# BL808 register map
File version: 0.1
Registers are access not given, no defined reset value unless marked. A register's access mark holds for its fields unless they carry their own. Offsets are from the block's base; [hi:lo] are bit positions.

## IR
Base 0x2000A600
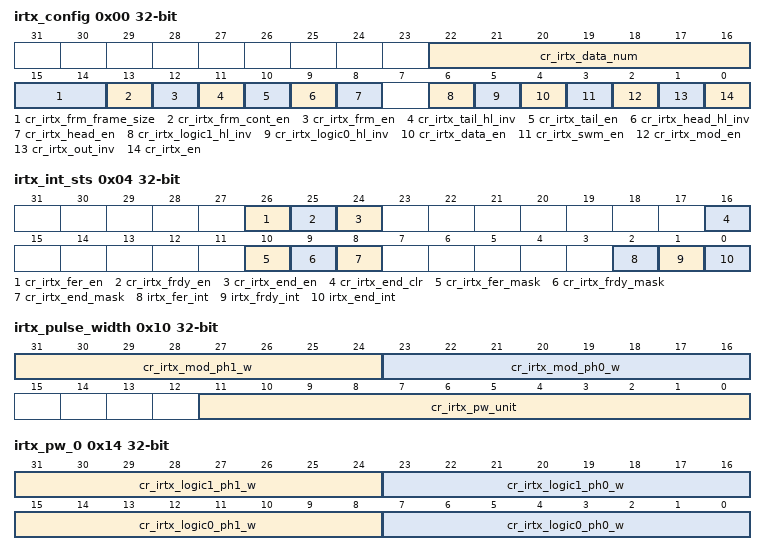
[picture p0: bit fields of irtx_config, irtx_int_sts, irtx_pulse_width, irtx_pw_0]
0x00 irtx_config
  [22:16] cr_irtx_data_num rw — Bit count of Data phase (unit: bit / PW for normal / SWM) (Don't-care if cr_irtx_frm_en is enabled)
  [15:14] cr_irtx_frm_frame_size rw — IRTX freerun mode frame size (also the valid width for each FIFO entry) 2'd0: 8-bit 2'd1: 16-bit 2'd2: 24-bit 2'd3: 32-bit
  [13] cr_irtx_frm_cont_en rw — Enable signal of IRTX freerun continuous mode 0: Disabled, each data frame is separated by an idle time (tail_ph0_w+1 + tail_ph1_w+1)*pw_unit 1: Enabled, data continuously sent without interval (if FIFO data is valid)
  [12] cr_irtx_frm_en rw — Enable signal of IRTX freerun mode (Don't care if SWM is enabled) Note: HEAD/TAIL is disabled in freerun mode
  [11] cr_irtx_tail_hl_inv rw — Tail pulse H/L inverse signal (Don't care if SWM or FRM is enabled) 0: Phase 0 is High (Active), phase 1 is Low (Idle) (H -> L) 1: Phase 0 is Low (Idle), phase 1 is High (Active) (L -> H)
  [10] cr_irtx_tail_en rw — Enable signal of tail pulse (Don't care if SWM or FRM is enabled)
  [9] cr_irtx_head_hl_inv rw — Tail pulse H/L inverse signal (Don't care if SWM or FRM is enabled) 0: Phase 0 is High (Active), phase 1 is Low (Idle) (H -> L) 1: Phase 0 is Low (Idle), phase 1 is High (Active) (L -> H)
  [8] cr_irtx_head_en rw — Enable signal of head pulse (Don't care if SWM or FRM is enabled)
  [6] cr_irtx_logic1_hl_inv rw — Logic 1 H/L inverse signal (Don't care if SWM is enabled) 0: Phase 0 is High (Active), phase 1 is Low (Idle) (H -> L) 1: Phase 0 is Low (Idle), phase 1 is High (Active) (L -> H)
  [5] cr_irtx_logic0_hl_inv rw — Logic 0 H/L inverse signal (Don't care if SWM is enabled) 0: Phase 0 is High (Active), phase 1 is Low (Idle) (H -> L) 1: Phase 0 is Low (Idle), phase 1 is High (Active) (L -> H)
  [4] cr_irtx_data_en rw — Enable signal of data phase (Don't care if SWM or FRM is enabled)
  [3] cr_irtx_swm_en rw — Enable signal of IRTX Software Mode (SWM)
  [2] cr_irtx_mod_en rw — Enable signal of output modulation
  [1] cr_irtx_out_inv rw — Output inverse signal 1'b0: Output stays at Low during idle state 1'b1: Output stays at High during idle state
  [0] cr_irtx_en rw — Enable signal of IRTX function Asserting this bit will trigger the transaction, and should be de-asserted after finish
0x04 irtx_int_sts
  [26] cr_irtx_fer_en rw — Interrupt enable of irtx_fer_int
  [25] cr_irtx_frdy_en rw — Interrupt enable of irtx_frdy_int
  [24] cr_irtx_end_en rw — Interrupt enable of irtx_end_int
  [16] cr_irtx_end_clr write-once — Interrupt clear of irtx_end_int
  [10] cr_irtx_fer_mask rw — Interrupt mask of irtx_fer_int
  [9] cr_irtx_frdy_mask rw — Interrupt mask of irtx_frdy_int
  [8] cr_irtx_end_mask rw — Interrupt mask of irtx_end_int
  [2] irtx_fer_int ro — IRTX FIFO error interrupt, auto-cleared when FIFO overflow/underflow error flag is cleared
  [1] irtx_frdy_int ro — IRTX FIFO ready (tx_fifo_cnt > tx_fifo_th) interrupt, auto-cleared when data is pushed
  [0] irtx_end_int ro — IRTX transfer end interrupt
0x10 irtx_pulse_width
  [31:24] cr_irtx_mod_ph1_w rw — Modulation phase 1 width
  [23:16] cr_irtx_mod_ph0_w rw — Modulation phase 0 width
  [11:0] cr_irtx_pw_unit rw — Pulse width unit
0x14 irtx_pw_0 rw
  [31:24] cr_irtx_logic1_ph1_w — Pulse width of logic1 phase 1 (Don't care if SWM is enabled)
  [23:16] cr_irtx_logic1_ph0_w — Pulse width of logic1 phase 0 (Don't care if SWM is enabled)
  [15:8] cr_irtx_logic0_ph1_w — Pulse width of logic0 phase 1 (Don't care if SWM is enabled)
  [7:0] cr_irtx_logic0_ph0_w — Pulse width of logic0 phase 0 (Don't care if SWM is enabled)
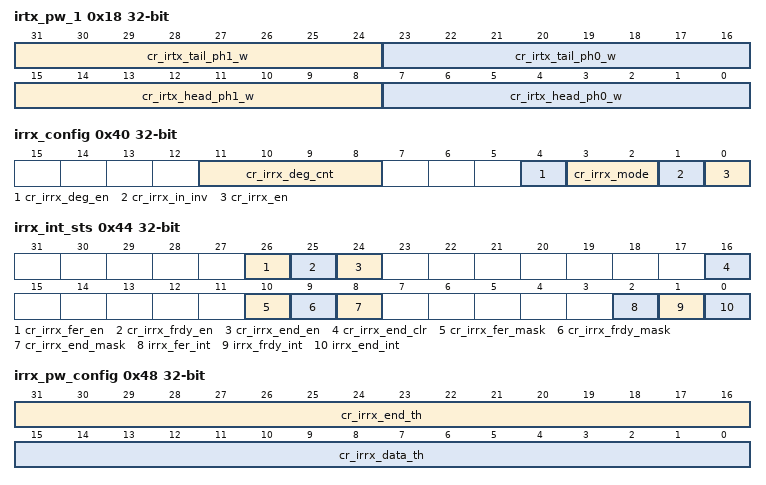
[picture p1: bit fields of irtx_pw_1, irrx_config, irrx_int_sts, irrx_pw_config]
0x18 irtx_pw_1 rw
  [31:24] cr_irtx_tail_ph1_w — Pulse width of tail pulse phase 1 (Don't care if SWM is enabled)
  [23:16] cr_irtx_tail_ph0_w — Pulse width of tail pulse phase 0 (Don't care if SWM is enabled)
  [15:8] cr_irtx_head_ph1_w — Pulse width of head pulse phase 1 (Don't care if SWM is enabled)
  [7:0] cr_irtx_head_ph0_w — Pulse width of head pulse phase 0 (Don't care if SWM is enabled)
0x40 irrx_config
  [11:8] cr_irrx_deg_cnt rw — De-glitch function cycle count
  [4] cr_irrx_deg_en rw — Enable signal of IRRX input de-glitch function
  [3:2] cr_irrx_mode rw — IRRX mode 0: NEC 1: RC5 2: SW pulse-width detection mode (SWM) 3: Reserved
  [1] cr_irrx_in_inv rw — Input inverse signal
  [0] cr_irrx_en rw — Enable signal of IRRX function Asserting this bit will trigger the transaction, and should be de-asserted after finish
0x44 irrx_int_sts
  [26] cr_irrx_fer_en rw — Interrupt enable of irrx_fer_int
  [25] cr_irrx_frdy_en rw — Interrupt enable of irrx_frdy_int
  [24] cr_irrx_end_en rw — Interrupt enable of irrx_end_int
  [16] cr_irrx_end_clr write-once — Interrupt clear of irrx_end_int
  [10] cr_irrx_fer_mask rw — Interrupt mask of irrx_fer_int
  [9] cr_irrx_frdy_mask rw — Interrupt mask of irrx_frdy_int
  [8] cr_irrx_end_mask rw — Interrupt mask of irrx_end_int
  [2] irrx_fer_int ro — IRRX FIFO error interrupt, auto-cleared when FIFO overflow/underflow error flag is cleared
  [1] irrx_frdy_int ro — IRRX FIFO ready (rx_fifo_cnt > rx_fifo_th) interrupt, auto-cleared when data is popped
  [0] irrx_end_int ro — IRRX transfer end interrupt
0x48 irrx_pw_config rw
  [31:16] cr_irrx_end_th — Pulse width threshold to trigger END condition
  [15:0] cr_irrx_data_th — Pulse width threshold for Logic0/1 detection (Don't care if SWM is enabled)
0x50 irrx_data_count
  [6:0] sts_irrx_data_cnt ro — RX data bit count (pulse-width count for SWM)
0x54 irrx_data_word0 ro
  [31:0] sts_irrx_data_word0 — RX data word 0
0x58 irrx_data_word1 ro
  [31:0] sts_irrx_data_word1 — RX data word 1
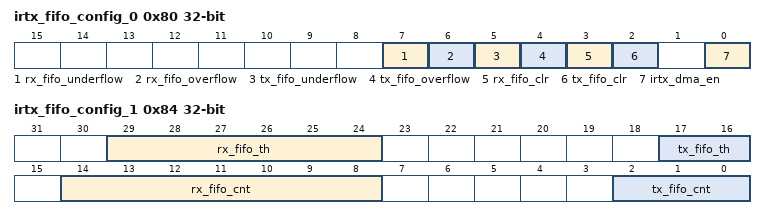
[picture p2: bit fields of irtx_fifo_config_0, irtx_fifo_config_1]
0x80 irtx_fifo_config_0
  [7] rx_fifo_underflow ro — Underflow flag of RX FIFO, can be cleared by rx_fifo_clr
  [6] rx_fifo_overflow ro — Overflow flag of RX FIFO, can be cleared by rx_fifo_clr
  [5] tx_fifo_underflow ro — Underflow flag of TX FIFO, can be cleared by tx_fifo_clr
  [4] tx_fifo_overflow ro — Overflow flag of TX FIFO, can be cleared by tx_fifo_clr
  [3] rx_fifo_clr write-once — Clear signal of RX FIFO
  [2] tx_fifo_clr write-once — Clear signal of TX FIFO
  [0] irtx_dma_en rw — Enable signal of dma_tx_req/ack interface
0x84 irtx_fifo_config_1
  [29:24] rx_fifo_th rw — RX FIFO threshold, irrx_frdy_int will not be asserted if rx_fifo_cnt is less than this value
  [17:16] tx_fifo_th rw — TX FIFO threshold, irtx_frdy_int & dma_tx_req will not be asserted if tx_fifo_cnt is less than this value
  [14:8] rx_fifo_cnt ro — RX FIFO available count
  [2:0] tx_fifo_cnt ro — TX FIFO available count
0x88 ir_fifo_wdata wo
  [31:0] tx_fifo_wdata — IRTX FIFO data Normal Mode: Each entry contains a 32-bit data word, LSB is sent first Software Mode: Each entry contains 4 pulse widths, [7:0] is the 1st pulse, [15:8] is the 2nd pulse, etc)
0x8C ir_fifo_rdata
  [15:0] rx_fifo_rdata ro — IRRX FIFO pulse width data for Software Mode
